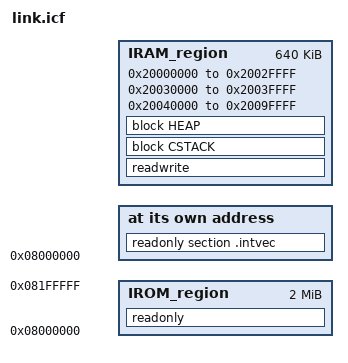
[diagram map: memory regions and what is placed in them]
/*###ICF### Section handled by ICF editor, don't touch! ****/
/*-Editor annotation file-*/
/* IcfEditorFile="$TOOLKIT_DIR$\config\ide\IcfEditor\cortex_v1_1.xml" */
/*-Specials-*/
define symbol __ICFEDIT_intvec_start__ = 0x08000000;
/*-Memory Regions-*/
define symbol __ICFEDIT_region_IROM1_start__ = 0x08000000;
define symbol __ICFEDIT_region_IROM1_end__   = 0x081FFFFF;
define symbol __ICFEDIT_region_IRAM1_start__ = 0x20000000;
define symbol __ICFEDIT_region_IRAM1_end__   = 0x2002FFFF;
define symbol __ICFEDIT_region_IRAM2_start__ = 0x20030000;
define symbol __ICFEDIT_region_IRAM2_end__   = 0x2003FFFF;

/*-Sizes-*/
define symbol __ICFEDIT_size_cstack__ = 0x2000;
define symbol __ICFEDIT_size_heap__   = 0x000;
/**** End of ICF editor section. ###ICF###*/

define symbol IRAM3_region_start   = 0x20040000;
define symbol IRAM3_region_end     = 0x2009FFFF;

define memory mem with size = 4G;
define region IROM_region   =   mem:[from __ICFEDIT_region_IROM1_start__ to __ICFEDIT_region_IROM1_end__];

define region IRAM_region   =   mem:[from __ICFEDIT_region_IRAM1_start__ to __ICFEDIT_region_IRAM1_end__]
                              | mem:[from __ICFEDIT_region_IRAM2_start__ to __ICFEDIT_region_IRAM2_end__]
                              | mem:[from IRAM3_region_start to IRAM3_region_end ];


define block CSTACK    with alignment = 8, size = __ICFEDIT_size_cstack__   { };
define block HEAP      with alignment = 8, size = __ICFEDIT_size_heap__     { };

initialize by copy { readwrite };

if (isdefinedsymbol(__USE_DLIB_PERTHREAD))
{
  // Required in a multi-threaded application
  initialize by copy with packing = none { section __DLIB_PERTHREAD };
}


place at address mem:__ICFEDIT_intvec_start__ { readonly section .intvec };

place in IROM_region  { readonly };
place in IRAM_region  { readwrite, block CSTACK, block HEAP };
